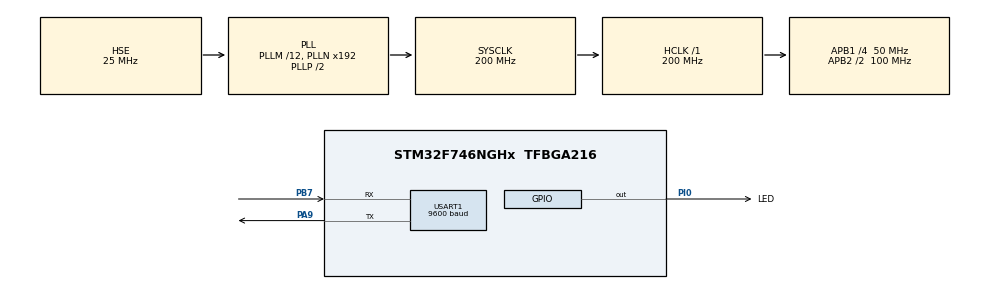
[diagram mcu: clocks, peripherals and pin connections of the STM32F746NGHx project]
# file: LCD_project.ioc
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CORTEX_M7.ART_ACCLERATOR_ENABLE=1
CORTEX_M7.CPU_DCache=Enabled
CORTEX_M7.CPU_ICache=Enabled
CORTEX_M7.PREFETCH_ENABLE=1
Mcu.Family=STM32F7
Mcu.Name=STM32F746NGHx
Mcu.Package=TFBGA216
NVIC.PriorityGroup=NVIC_PRIORITYGROUP_4
NVIC.RCC_IRQn=true\:0\:0\:false\:false\:true\:true\:false
NVIC.USART1_IRQn=true\:0\:0\:false\:false\:true\:true\:true
PA9.Mode=Asynchronous
PA9.Signal=USART1_TX
PB7.Mode=Asynchronous
PB7.Signal=USART1_RX
PH0/OSC_IN.Mode=HSE-External-Oscillator
PH0/OSC_IN.Signal=RCC_OSC_IN
PH1/OSC_OUT.Mode=HSE-External-Oscillator
PH1/OSC_OUT.Signal=RCC_OSC_OUT
PI0.GPIO_Label=LED
PI0.Signal=GPIO_Output
ProjectManager.HeapSize=0x200
ProjectManager.StackSize=0x400
ProjectManager.TargetToolchain=STM32CubeIDE
RCC.AHBFreq_Value=200000000
RCC.APB1CLKDivider=RCC_HCLK_DIV4
RCC.APB1Freq_Value=50000000
RCC.APB1TimFreq_Value=100000000
RCC.APB2CLKDivider=RCC_HCLK_DIV2
RCC.APB2Freq_Value=100000000
RCC.APB2TimFreq_Value=200000000
RCC.CortexFreq_Value=200000000
RCC.HCLKFreq_Value=200000000
RCC.HSE_VALUE=25000000
RCC.HSI_VALUE=16000000
RCC.LSE_VALUE=32768
RCC.PLLM=12
RCC.PLLSourceVirtual=RCC_PLLSOURCE_HSE
RCC.SYSCLKFreq_VALUE=200000000
RCC.SYSCLKSource=RCC_SYSCLKSOURCE_PLLCLK
RCC.USBFreq_Value=200000000
RCC.VCOOutputFreq_Value=400000000
USART1.BaudRate=9600
USART1.VirtualMode-Asynchronous=VM_ASYNC
VP_CRC_VS_CRC.Mode=CRC_Activate
VP_DMA2D_VS_DMA2D.Mode=DMA2D_Activate
board=custom

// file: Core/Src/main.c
/* USER CODE BEGIN Header */
/**
  ******************************************************************************
  * @file           : main.c
  * @brief          : Main program body
  ******************************************************************************
  * @attention
  *
  * <h2><center>&copy; Copyright (c) 2024 STMicroelectronics.
  * All rights reserved.</center></h2>
  *
  * This software component is licensed by ST under BSD 3-Clause license,
  * the "License"; You may not use this file except in compliance with the
  * License. You may obtain a copy of the License at:
  *                        opensource.org/licenses/BSD-3-Clause
  *
  ******************************************************************************
  */
/* USER CODE END Header */
#include "main.h"
#include "my_lcd.h"

/* USER CODE BEGIN Includes */
#include <stdio.h>
#include <stdlib.h>
#include <string.h>
/* USER CODE END Includes */

CRC_HandleTypeDef hcrc;

DMA2D_HandleTypeDef hdma2d;

UART_HandleTypeDef huart1;

void SystemClock_Config(void);
static void MX_GPIO_Init(void);
static void MX_CRC_Init(void);
static void MX_DMA2D_Init(void);
static void MX_USART1_UART_Init(void);

/* USER CODE BEGIN 0 */
uint8_t rcv_buff;
char rcv_line[RCV_SIZE];
int count  = 0, rcv_flag = 0;

const char *nums_str[]  = { "0", "1", "2", "3", "4", "5", "6", "7", "8", "9" };

void SendData ( char *TRS_line, int *cnt_t ) {
	int buff_size = (*cnt_t) + 2;
	char buff[buff_size];

	My_strcpy ( buff, TRS_line, 0, buff_size - 2 );

	buff[buff_size - 2] = '\n';
	buff[buff_size - 1] = '\r';
	TRS_line[0] = '\0';
	(*cnt_t) = 0;

	HAL_UART_Transmit(&huart1, (uint8_t *) buff, buff_size, 200);

	return;
}
/* USER CODE END 0 */

int main(void)
{

  /* Enable I-Cache---------------------------------------------------------*/
  SCB_EnableICache();

  /* Enable D-Cache---------------------------------------------------------*/
  SCB_EnableDCache();

  /* MCU Configuration--------------------------------------------------------*/

  /* Reset of all peripherals, Initializes the Flash interface and the Systick. */
  HAL_Init();

  /* Configure the system clock */
  SystemClock_Config();

  /* Initialize all configured peripherals */
  MX_GPIO_Init();
  MX_CRC_Init();
  MX_DMA2D_Init();
  MX_USART1_UART_Init();
  /* USER CODE BEGIN 2 */

  BSP_SDRAM_Init(); /* Initializes the SDRAM device */
    __HAL_RCC_CRC_CLK_ENABLE(); /* Enable the CRC Module */

    BSP_TS_Init(480, 272);

    BSP_LCD_Init();
    BSP_LCD_LayerDefaultInit(0, LCD_FB_START_ADDRESS);
    BSP_LCD_DisplayOn();

    BSP_LCD_SelectLayer(0);
    BSP_LCD_SetTextColor(LCD_COLOR_BLACK);
    BSP_LCD_Clear(LCD_COLOR_WHITE);

	TS_StateTypeDef  ts;
	char xTouchStr[10];

    BUTTON_st *num_but[10];

    for( int i = 0; i < 5; ++i ) {
    	num_but[i] = CreateButton (20 + 90 * i      , 165, 80, 40, nums_str[i], 1);
    }
    for( int i = 5; i < 10; ++i ) {
    	num_but[i] = CreateButton (20 + 90 * (i - 5), 215, 80, 40, nums_str[i], 1);
    }

    BUTTON_st *ASCII = CreateButton(10 , 20 , 110, 40, "ASCII", 5);
    BUTTON_st *TRS   = CreateButton(10 , 70 , 70 , 40, "TRS"  , 3);
    BUTTON_st *RCV   = CreateButton(10 , 120, 70 , 40, "RCV"  , 3);
    BUTTON_st *PRINT = CreateButton(360, 20 , 110, 40, "PRINT", 5);
    BUTTON_st *SEND  = CreateButton(380, 70 , 90 , 40, "SEND" , 4);

    BUTTON_st *all_buttons[15];
    for( int i = 0; i < 10; ++i ) {
    	all_buttons[i] = num_but[i];
    	DrawButton(all_buttons[i]);
    }

    	all_buttons[10] = ASCII;
    	DrawButton(all_buttons[10]);

    	all_buttons[11] = TRS;
    	DrawButton(all_buttons[11]);

    	all_buttons[12] = RCV;
    	DrawButton(all_buttons[12]);

    	all_buttons[13] = PRINT;
    	DrawButton(all_buttons[13]);

    	all_buttons[14] = SEND;
    	DrawButton(all_buttons[14]);

    	BSP_LCD_DrawRect(190, 20, 160, 40);
    	BSP_LCD_DisplayStringAt(195, 30, (uint8_t *) "CHAR:", LEFT_MODE);

    	char ASCII_line[ASCII_SIZE];
    	char TRS_line  [TRS_SIZE  ];
    	char RCV_line  [RCV_SIZE  ];
    	char CHAR_line [CHAR_SIZE ];

    	int cnt_a = 0, cnt_t = 0, cnt_r = 0;
    	int char_flag = 0;

    	ASCII_line[0] = TRS_line[0] = RCV_line[0] = CHAR_line[0] = '\0';

  /* USER CODE END 2 */

  /* Infinite loop */
  /* USER CODE BEGIN WHILE */

  HAL_UART_Receive_IT(&huart1,  &rcv_buff, 1);
  while (1)
  {
    /* USER CODE END WHILE */

    /* USER CODE BEGIN 3 */
	ScanScreen

	uint16_t X = ts.touchX[0];
	uint16_t Y = ts.touchY[0];

	ButtonResponse( X, Y, all_buttons, ASCII_line, TRS_line, RCV_line, CHAR_line, &cnt_a, &cnt_t, &cnt_r, &char_flag );

	UpdateScreen( all_buttons, ASCII_line, TRS_line, RCV_line, CHAR_line );

	HAL_Delay(150);
  }

  /* USER CODE END 3 */
}

void HAL_UART_RxCpltCallback(UART_HandleTypeDef *huart){
		if(rcv_buff == '\r')
		 {
			rcv_line[count] = '\0';

			rcv_flag = count;

			count = 0;
		 }
		 else
		 {
			 rcv_line[count] = rcv_buff;
			 ++count;
		 }
		 HAL_UART_Receive_IT(&huart1, &rcv_buff, 1);

}

void SystemClock_Config(void)
{
  RCC_OscInitTypeDef RCC_OscInitStruct = {0};
  RCC_ClkInitTypeDef RCC_ClkInitStruct = {0};
  RCC_PeriphCLKInitTypeDef PeriphClkInitStruct = {0};

  /** Configure the main internal regulator output voltage
  */
  __HAL_RCC_PWR_CLK_ENABLE();
  __HAL_PWR_VOLTAGESCALING_CONFIG(PWR_REGULATOR_VOLTAGE_SCALE1);
  /** Initializes the RCC Oscillators according to the specified parameters
  * in the RCC_OscInitTypeDef structure.
  */
  RCC_OscInitStruct.OscillatorType = RCC_OSCILLATORTYPE_HSE;
  RCC_OscInitStruct.HSEState = RCC_HSE_ON;
  RCC_OscInitStruct.PLL.PLLState = RCC_PLL_ON;
  RCC_OscInitStruct.PLL.PLLSource = RCC_PLLSOURCE_HSE;
  RCC_OscInitStruct.PLL.PLLM = 12;
  RCC_OscInitStruct.PLL.PLLN = 192;
  RCC_OscInitStruct.PLL.PLLP = RCC_PLLP_DIV2;
  RCC_OscInitStruct.PLL.PLLQ = 2;
  if (HAL_RCC_OscConfig(&RCC_OscInitStruct) != HAL_OK)
  {
    Error_Handler();
  }
  /** Activate the Over-Drive mode
  */
  if (HAL_PWREx_EnableOverDrive() != HAL_OK)
  {
    Error_Handler();
  }
  /** Initializes the CPU, AHB and APB buses clocks
  */
  RCC_ClkInitStruct.ClockType = RCC_CLOCKTYPE_HCLK|RCC_CLOCKTYPE_SYSCLK
                              |RCC_CLOCKTYPE_PCLK1|RCC_CLOCKTYPE_PCLK2;
  RCC_ClkInitStruct.SYSCLKSource = RCC_SYSCLKSOURCE_PLLCLK;
  RCC_ClkInitStruct.AHBCLKDivider = RCC_SYSCLK_DIV1;
  RCC_ClkInitStruct.APB1CLKDivider = RCC_HCLK_DIV4;
  RCC_ClkInitStruct.APB2CLKDivider = RCC_HCLK_DIV2;

  if (HAL_RCC_ClockConfig(&RCC_ClkInitStruct, FLASH_LATENCY_6) != HAL_OK)
  {
    Error_Handler();
  }
  PeriphClkInitStruct.PeriphClockSelection = RCC_PERIPHCLK_USART1;
  PeriphClkInitStruct.Usart1ClockSelection = RCC_USART1CLKSOURCE_PCLK2;
  if (HAL_RCCEx_PeriphCLKConfig(&PeriphClkInitStruct) != HAL_OK)
  {
    Error_Handler();
  }
}

static void MX_CRC_Init(void)
{

  hcrc.Instance = CRC;
  hcrc.Init.DefaultPolynomialUse = DEFAULT_POLYNOMIAL_ENABLE;
  hcrc.Init.DefaultInitValueUse = DEFAULT_INIT_VALUE_ENABLE;
  hcrc.Init.InputDataInversionMode = CRC_INPUTDATA_INVERSION_NONE;
  hcrc.Init.OutputDataInversionMode = CRC_OUTPUTDATA_INVERSION_DISABLE;
  hcrc.InputDataFormat = CRC_INPUTDATA_FORMAT_BYTES;
  if (HAL_CRC_Init(&hcrc) != HAL_OK)
  {
    Error_Handler();
  }

}

static void MX_DMA2D_Init(void)
{

  hdma2d.Instance = DMA2D;
  hdma2d.Init.Mode = DMA2D_M2M;
  hdma2d.Init.ColorMode = DMA2D_OUTPUT_ARGB8888;
  hdma2d.Init.OutputOffset = 0;
  hdma2d.LayerCfg[1].InputOffset = 0;
  hdma2d.LayerCfg[1].InputColorMode = DMA2D_INPUT_ARGB8888;
  hdma2d.LayerCfg[1].AlphaMode = DMA2D_NO_MODIF_ALPHA;
  hdma2d.LayerCfg[1].InputAlpha = 0;
  if (HAL_DMA2D_Init(&hdma2d) != HAL_OK)
  {
    Error_Handler();
  }
  if (HAL_DMA2D_ConfigLayer(&hdma2d, 1) != HAL_OK)
  {
    Error_Handler();
  }

}

static void MX_USART1_UART_Init(void)
{

  huart1.Instance = USART1;
  huart1.Init.BaudRate = 9600;
  huart1.Init.WordLength = UART_WORDLENGTH_8B;
  huart1.Init.StopBits = UART_STOPBITS_1;
  huart1.Init.Parity = UART_PARITY_NONE;
  huart1.Init.Mode = UART_MODE_TX_RX;
  huart1.Init.HwFlowCtl = UART_HWCONTROL_NONE;
  huart1.Init.OverSampling = UART_OVERSAMPLING_16;
  huart1.Init.OneBitSampling = UART_ONE_BIT_SAMPLE_DISABLE;
  huart1.AdvancedInit.AdvFeatureInit = UART_ADVFEATURE_NO_INIT;
  if (HAL_UART_Init(&huart1) != HAL_OK)
  {
    Error_Handler();
  }

}

static void MX_GPIO_Init(void)
{
  GPIO_InitTypeDef GPIO_InitStruct = {0};

  /* GPIO Ports Clock Enable */
  __HAL_RCC_GPIOB_CLK_ENABLE();
  __HAL_RCC_GPIOI_CLK_ENABLE();
  __HAL_RCC_GPIOA_CLK_ENABLE();
  __HAL_RCC_GPIOH_CLK_ENABLE();

  /*Configure GPIO pin Output Level */
  HAL_GPIO_WritePin(LED_GPIO_Port, LED_Pin, GPIO_PIN_RESET);

  /*Configure GPIO pin : LED_Pin */
  GPIO_InitStruct.Pin = LED_Pin;
  GPIO_InitStruct.Mode = GPIO_MODE_OUTPUT_PP;
  GPIO_InitStruct.Pull = GPIO_NOPULL;
  GPIO_InitStruct.Speed = GPIO_SPEED_FREQ_LOW;
  HAL_GPIO_Init(LED_GPIO_Port, &GPIO_InitStruct);

}

void Error_Handler(void)
{
  __disable_irq();
  while (1)
  {
  }
}

/************************ (C) COPYRIGHT STMicroelectronics *****END OF FILE****/
